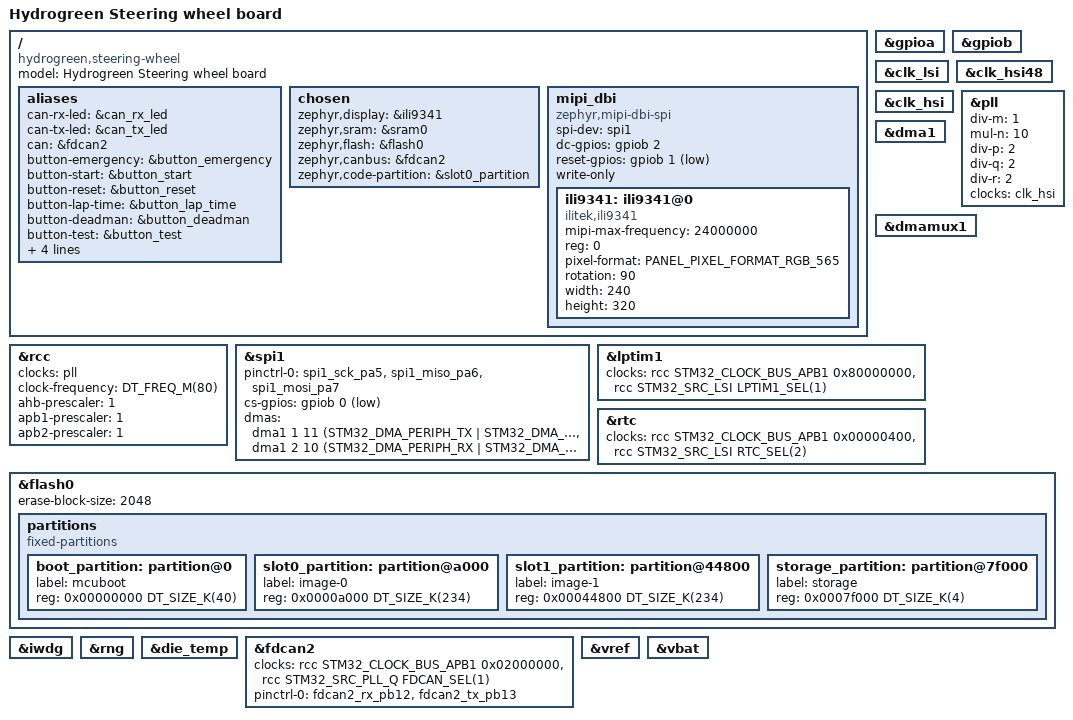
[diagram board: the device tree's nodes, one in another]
/dts-v1/;
#include <st/g4/stm32g491Xe.dtsi>
#include <st/g4/stm32g491c(c-e)tx-pinctrl.dtsi>
#include <zephyr/dt-bindings/display/panel.h>
#include <zephyr/dt-bindings/mipi_dbi/mipi_dbi.h>
#include <zephyr/dt-bindings/led/led.h>
#include <zephyr/dt-bindings/input/input-event-codes.h>

/ {
	model = "Hydrogreen Steering wheel board";
	compatible = "hydrogreen,steering-wheel";

	aliases {
		can-rx-led = &can_rx_led;
		can-tx-led = &can_tx_led;
		can = &fdcan2;
		button-emergency = &button_emergency;
		button-start = &button_start;
		button-reset = &button_reset;
		button-lap-time = &button_lap_time;
		button-deadman = &button_deadman;
		button-test = &button_test;
		watchdog0 = &iwdg;
		die-temp0 = &die_temp;
		volt-sensor0 = &vref;
		volt-sensor1 = &vbat;
	};

	chosen {
		zephyr,display = &ili9341;
		zephyr,sram = &sram0;
		zephyr,flash = &flash0;
		zephyr,canbus = &fdcan2;
		zephyr,code-partition = &slot0_partition;
	};

	mipi_dbi {
		compatible = "zephyr,mipi-dbi-spi";
		spi-dev = <&spi1>;
		dc-gpios = <&gpiob 2 GPIO_ACTIVE_HIGH>;
		reset-gpios = <&gpiob 1 GPIO_ACTIVE_LOW>;
		write-only;
		#address-cells = <1>;
		#size-cells = <0>;
		status = "okay";

		ili9341: ili9341@0 {
			compatible = "ilitek,ili9341";
			mipi-max-frequency = <24000000>;
			reg = <0>;
			pixel-format = <PANEL_PIXEL_FORMAT_RGB_565>;
			//display-inversion;
			rotation = <90>;
			width = <240>;
			height = <320>;

			status = "okay";

		};
	};
};


&gpioa {
	status = "okay";
};

&gpiob {
	status = "okay";
};


&clk_lsi {
	status = "okay";
};

&clk_hsi48 {
	status = "okay";
};

//&clk_hse {
//	clock-frequency = <DT_FREQ_M(24)>;
//	status = "okay";
//};

&clk_hsi {
	//	clock-frequency = <DT_FREQ_M(16)>;
	status = "okay";
};

&pll {
	div-m = <1>;
	mul-n = <10>;
	div-p = <2>;
	div-q = <2>;
	div-r = <2>;
	clocks = <&clk_hsi>;
	status = "okay";
};

&rcc {
	clocks = <&pll>;
	clock-frequency = <DT_FREQ_M(80)>;
	ahb-prescaler = <1>;
	apb1-prescaler = <1>;
	apb2-prescaler = <1>;
};

// reference manual page 420 (dmamux)
//&usart1 {
//	pinctrl-0 = <&usart1_tx_pa9 &usart1_rx_pa10>;
//	pinctrl-names = "default";
//	current-speed = <115200>;
//	status = "okay";
//	dmas = <&dmamux1 2 25 STM32_DMA_PERIPH_TX>,
//		   <&dmamux1 1 24 STM32_DMA_PERIPH_RX>;
//	dma-names = "tx", "rx";
//};

&dma1 {
	status = "okay";
};

&dmamux1 {
	status = "okay";
};

&spi1 {
	pinctrl-0 = <&spi1_sck_pa5 &spi1_miso_pa6 &spi1_mosi_pa7>;
	pinctrl-names = "default";
	cs-gpios = <&gpiob 0 (GPIO_ACTIVE_LOW | GPIO_PULL_UP)>;

	dmas = <&dma1 1 11 (STM32_DMA_PERIPH_TX | STM32_DMA_PRIORITY_HIGH)>,
		   <&dma1 2 10 (STM32_DMA_PERIPH_RX | STM32_DMA_PRIORITY_HIGH)>;
	dma-names = "tx", "rx";

	status = "okay";
//
//	ili9341: display@0 {
//		compatible = "ilitek,ili9341";
//		reg = <0>;
//
//		spi-max-frequency = <24000000>;
//		mipi-max-frequency = <24000000>;
//		mipi-mode = "MIPI_DBI_MODE_SPI_4WIRE";
//
//		duplex = <0>;
//		frame-format = <0>;
//
//		width = <240>;
//		height = <320>;
//		pixel-format = <PANEL_PIXEL_FORMAT_RGB_565>;
//
//		cmd-data-gpios = <&gpiob 2 GPIO_ACTIVE_HIGH>;
//		reset-gpios = <&gpiob 1 GPIO_ACTIVE_LOW>;
//
//		rotation = <90>;
//		display-inversion;
//		status = "okay";
//	};
};

//&timers2 {
//	status = "okay";
//
//	pwm2: pwm {
//		status = "okay";
//		pinctrl-0 = <&tim2_ch1_pa5>;
//		pinctrl-names = "default";
//	};
//};
//
//&timers3 {
//	st,prescaler = <10000>;
//	status = "okay";
//	pwm3: pwm {
//		status = "okay";
//		pinctrl-0 = <&tim3_ch1_pb4>;
//		pinctrl-names = "default";
//	};
//};

stm32_lp_tick_source: &lptim1 {
	clocks = <&rcc STM32_CLOCK_BUS_APB1 0x80000000>,
			 <&rcc STM32_SRC_LSI LPTIM1_SEL(1)>;
	status = "okay";
};

&rtc {
	clocks = <&rcc STM32_CLOCK_BUS_APB1 0x00000400>,
			 <&rcc STM32_SRC_LSI RTC_SEL(2)>;
	status = "okay";
};

&flash0 {
	erase-block-size = <2048>;
	partitions {
		compatible = "fixed-partitions";
		#address-cells = <1>;
		#size-cells = <1>;

		boot_partition: partition@0 {
			label = "mcuboot";
			reg = <0x00000000 DT_SIZE_K(40)>;
		};
		slot0_partition: partition@a000 {
			label = "image-0";
			reg = <0x0000a000 DT_SIZE_K(234)>;
		};
		slot1_partition: partition@44800 {
			label = "image-1";
			reg = <0x00044800 DT_SIZE_K(234)>;
		};
		/* Set 4Kb of storage at the end of the 512Kb of flash */
		storage_partition: partition@7f000 {
			label = "storage";
			reg = <0x0007f000 DT_SIZE_K(4)>;
		};
	};
};

&iwdg {
	status = "okay";
};

&rng {
	status = "okay";
};


&die_temp {
	status = "okay";
};

//&fdcan1 {
//	clocks = <&rcc STM32_CLOCK_BUS_APB1 0x02000000>,
//			 <&rcc STM32_SRC_HSE FDCAN_SEL(0)>;
//	pinctrl-0 = <&fdcan1_rx_pa11 &fdcan1_tx_pa12>;
//	pinctrl-names = "default";
//	status = "okay";
//};

&fdcan2 {
	clocks = <&rcc STM32_CLOCK_BUS_APB1 0x02000000>,
			 <&rcc STM32_SRC_PLL_Q FDCAN_SEL(1)>;
	pinctrl-0 = <&fdcan2_rx_pb12 &fdcan2_tx_pb13>;
	pinctrl-names = "default";
	status = "okay";
};

&vref {
	status = "okay";
};

&vbat {
	status = "okay";
};

